# MSP430FR5962 register map
File version: 2.1
CPU: MSP430FR5962 r2p1, little endian, MPU, no FPU, 3 interrupt priority bits
Registers are 16-bit, read-write, reset 0x0 unless marked. A register's access mark holds for its fields unless they carry their own. Offsets are from the block's base; [hi:lo] are bit positions; {n}, {i} and the like mark numbered series.

## COMP_E
Base 0x000008C0
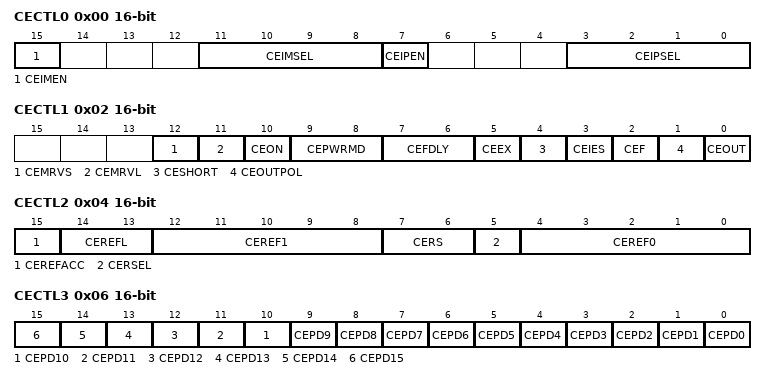
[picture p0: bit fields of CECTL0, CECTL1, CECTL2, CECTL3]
0x00 CECTL0 — Comparator Control Register 0
  [15] CEIMEN — [15:15] Channel input enable for the - terminal
    0=DISABLE (Selected analog input channel for V- terminal is disabled); 1=ENABLE (Selected analog input channel for V- terminal is enabled)
  [11:8] CEIMSEL — [11:8] Channel input selected for the - terminal
    {v}=Channel {v} selected (v=0..15)
  [7] CEIPEN — [7:7] Channel input enable for the V+ terminal
    0=DISABLE (Selected analog input channel for V+ terminal is disabled); 1=ENABLE (Selected analog input channel for V+ terminal is enabled)
  [3:0] CEIPSEL — [3:0] Channel input selected for the V+ terminal
    {v}=Channel {v} selected (v=0..15)
0x02 CECTL1 — Comparator Control Register 1
  [12] CEMRVS — [12:12] This bit defines if the comparator output selects between VREF0 or VREF1 if CERS = 00, 01, or 10.
    0=Comparator output state selects between VREF0 or VREF1; 1=CEMRVL selects between VREF0 or VREF1
  [11] CEMRVL — [11:11] This bit is valid of CEMRVS is set to 1
    0=VREF0 (VREF0 is selected if CERS = 00, 01, or 10); 1=VREF1 (VREF1 is selected if CERS = 00, 01, or 10)
  [10] CEON — [10:10] Comparator On
    0=OFF; 1=ON
  [9:8] CEPWRMD — [9:8] Power Mode
    0=High-speed mode; 1=Normal mode; 2=Ultra-low power mode
  [7:6] CEFDLY — [7:6] Filter delay
    0=Typical filter delay of TBD (450) ns; 1=Typical filter delay of TBD (900) ns; 2=Typical filter delay of TBD (1800) ns; 3=Typical filter delay of TBD (3600) ns
  [5] CEEX — [5:5] Exchange
  [4] CESHORT — [4:4] Input short
    0=Inputs not shorted; 1=Inputs shorted
  [3] CEIES — [3:3] Interrupt edge select for CEIIFG and CEIFG
    0=Rising edge for CEIFG, falling edge for CEIIFG; 1=Falling edge for CEIFG, rising edge for CEIIFG
  [2] CEF — [2:2] Comparator output filter
    0=Comparator output is not filtered; 1=Comparator output is filtered
  [1] CEOUTPOL — [1:1] Comparator output polarity
    0=Noninverted; 1=Inverted
  [0] CEOUT — [0:0] Comparator output value
0x04 CECTL2 — Comparator Control Register 2
  [15] CEREFACC — [15:15] Reference accuracy
    0=STATIC (Static mode); 1=CLOCKED (Clocked (low power, low accuracy) mode)
  [14:13] CEREFL — [14:13] Reference voltage level
    0=OFF (Reference amplifier is disabled. No reference voltage is requested); 1=1P2V (1.2 V is selected as shared reference voltage input); 2=2P0V (2.0 V is selected as shared reference voltage input); 3=2P5V (2.5 V is selected as shared reference voltage input)
  [12:8] CEREF1 — [12:8] Reference resistor tap 1
  [7:6] CERS — [7:6] Reference source
    0=No current is drawn by the reference circuitry; 1=VCC applied to the resistor ladder; 2=Shared reference voltage applied to the resistor ladder; 3=Shared reference voltage supplied to V(CREF). Resistor ladder is off
  [5] CERSEL — [5:5] Reference select
    0=When CEEX = 0, VREF is applied to the V+ terminal; When CEEX = 1, VREF is applied to the V- terminal; 1=When CEEX = 0, VREF is applied to the V- terminal; When CEEX = 1, VREF is applied to the V+ terminal
  [4:0] CEREF0 — [4:0] Reference resistor tap 0
0x06 CECTL3 — Comparator Control Register 3
  [all] fields
    0=The input buffer is enabled; 1=The input buffer is disabled
  [n] CEPD{n} (n=0..15) — [{n}:{n}] Port disable
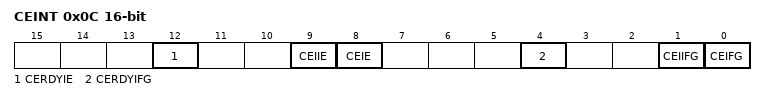
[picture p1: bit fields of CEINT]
0x0C CEINT — Comparator Interrupt Control Register
  [12] CERDYIE — [12:12] Comparator ready interrupt enable
    0=DISABLE (Interrupt disabled); 1=ENABLE (Interrupt enabled)
  [9] CEIIE — [9:9] Comparator output interrupt enable inverted polarity
    0=DISABLE (Interrupt disabled); 1=ENABLE (Interrupt enabled)
  [8] CEIE — [8:8] Comparator output interrupt enable
    0=DISABLE (Interrupt disabled); 1=ENABLE (Interrupt enabled)
  [4] CERDYIFG — [4:4] Comparator ready interrupt flag
    0=No interrupt pending; 1=Interrupt pending
  [1] CEIIFG — [1:1] Comparator output inverted interrupt flag
    0=No interrupt pending; 1=Interrupt pending
  [0] CEIFG — [0:0] Comparator output interrupt flag
    0=No interrupt pending; 1=Interrupt pending
0x0E CEIV — Comparator Interrupt Vector Word Register
  [15:0] CEIV — [15:0] Comparator interrupt vector word register
    0=NONE (No interrupt pending); 2=CEIFG (Interrupt Source: CEOUT interrupt; Interrupt Flag: CEIFG; Interrupt Priority: Highest); 4=CEIIFG (Interrupt Source: CEOUT interrupt inverted polarity; Interrupt Flag: CEIIFG); 10=CERDYIFG (Interrupt Source: Comparator ready interrupt; Interrupt Flag: CERDYIFG; Interrupt Priority: Lowest)
